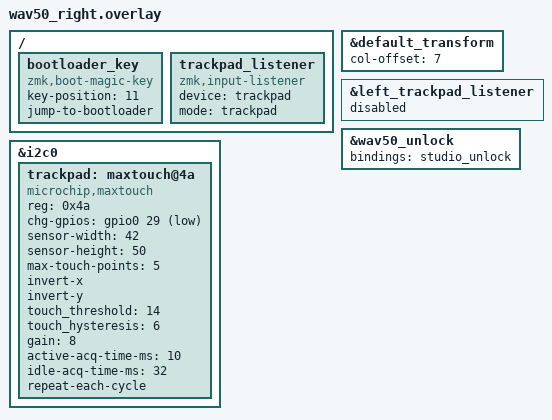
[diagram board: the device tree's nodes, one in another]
#include "wav50.dtsi"

/ {
    bootloader_key: bootloader_key {
        compatible = "zmk,boot-magic-key";
        key-position = <11>;
        jump-to-bootloader;
    };
};

&default_transform {
    col-offset = <7>;
};

&i2c0 {
    status = "okay";

    trackpad: maxtouch@4a {
        compatible = "microchip,maxtouch";
        status = "okay";
        reg = <0x4a>;
        chg-gpios = <&gpio0 29 (GPIO_ACTIVE_LOW | GPIO_PULL_UP)>;
        sensor-width = <42>;
        sensor-height = <50>;
        max-touch-points = <5>;
        invert-x;
        invert-y;
        touch_threshold = <14>;
        touch_hysteresis = <6>;
        gain = <8>;
        active-acq-time-ms = <10>;
        idle-acq-time-ms = <32>;
        repeat-each-cycle;
    };
};

/ {
    trackpad_listener {
        compatible = "zmk,input-listener";
        device = <&trackpad>;
        mode = "trackpad";
    };
};

&left_trackpad_listener {
    status = "disabled";
};

&wav50_unlock {
    bindings = <&studio_unlock>;
};
